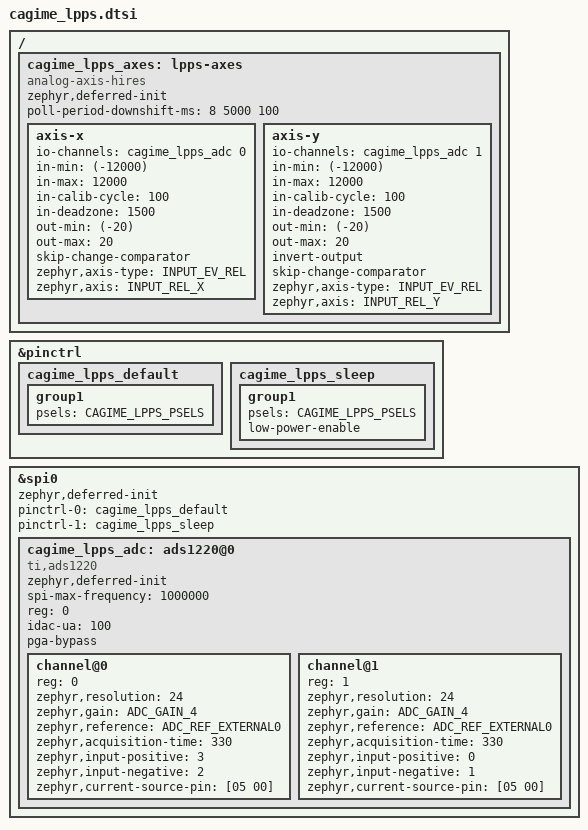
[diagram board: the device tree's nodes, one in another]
/* ADS1220 LPPS FPC pads 4 (SCLK), 1 (DIN), 2 (DOUT). */
&pinctrl {
    cagime_lpps_default: cagime_lpps_default {
        group1 {
            psels = CAGIME_LPPS_PSELS;
        };
    };

    cagime_lpps_sleep: cagime_lpps_sleep {
        group1 {
            psels = CAGIME_LPPS_PSELS;
            low-power-enable;
        };
    };
};

&spi0 {
    status = "okay";
    zephyr,deferred-init;
    pinctrl-0 = <&cagime_lpps_default>;
    pinctrl-1 = <&cagime_lpps_sleep>;
    pinctrl-names = "default", "sleep";

    /* CS is strapped on the module. Retain MeKaBu's timed conversion reads. */
    cagime_lpps_adc: ads1220@0 {
        compatible = "ti,ads1220";
        zephyr,deferred-init;
        spi-max-frequency = <1000000>;
        reg = <0>;
        idac-ua = <100>;
        pga-bypass;
        #io-channel-cells = <1>;
        #address-cells = <1>;
        #size-cells = <0>;

        channel@0 {
            reg = <0>;
            zephyr,resolution = <24>;
            zephyr,gain = "ADC_GAIN_4";
            zephyr,reference = "ADC_REF_EXTERNAL0";
            zephyr,acquisition-time = <330>;
            zephyr,input-positive = <3>;
            zephyr,input-negative = <2>;
            zephyr,current-source-pin = [05 00];
        };

        channel@1 {
            reg = <1>;
            zephyr,resolution = <24>;
            zephyr,gain = "ADC_GAIN_4";
            zephyr,reference = "ADC_REF_EXTERNAL0";
            zephyr,acquisition-time = <330>;
            zephyr,input-positive = <0>;
            zephyr,input-negative = <1>;
            zephyr,current-source-pin = [05 00];
        };
    };
};

/ {
    cagime_lpps_axes: lpps-axes {
        compatible = "analog-axis-hires";
        zephyr,deferred-init;
        poll-period-downshift-ms = <8 5000 100>;

        axis-x {
            status = "okay";
            io-channels = <&cagime_lpps_adc 0>;
            in-min = <(-12000)>;
            in-max = <12000>;
            in-calib-cycle = <100>;
            in-deadzone = <1500>;
            out-min = <(-20)>;
            out-max = <20>;
            skip-change-comparator;
            zephyr,axis-type = <INPUT_EV_REL>;
            zephyr,axis = <INPUT_REL_X>;
        };

        axis-y {
            status = "okay";
            io-channels = <&cagime_lpps_adc 1>;
            in-min = <(-12000)>;
            in-max = <12000>;
            in-calib-cycle = <100>;
            in-deadzone = <1500>;
            out-min = <(-20)>;
            out-max = <20>;
            invert-output;
            skip-change-comparator;
            zephyr,axis-type = <INPUT_EV_REL>;
            zephyr,axis = <INPUT_REL_Y>;
        };
    };
};
